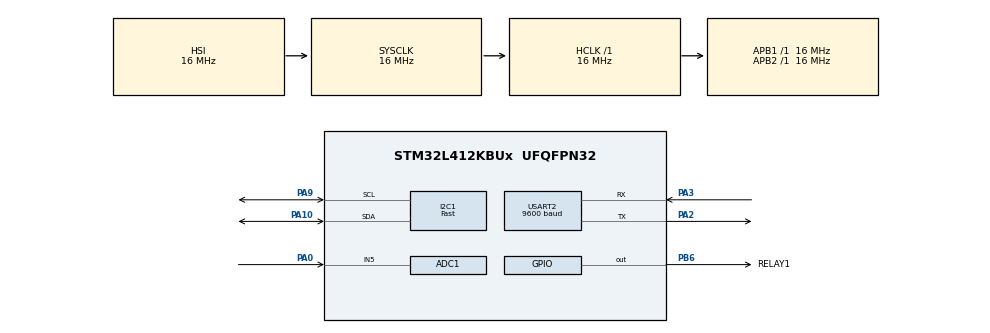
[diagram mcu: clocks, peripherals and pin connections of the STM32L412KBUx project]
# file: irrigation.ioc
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ADC1.Channel-0\#ChannelRegularConversion=ADC_CHANNEL_5
ADC1.NbrOfConversionFlag=1
ADC1.OffsetNumber-0\#ChannelRegularConversion=ADC_OFFSET_NONE
ADC1.Rank-0\#ChannelRegularConversion=1
ADC1.SamplingTime-0\#ChannelRegularConversion=ADC_SAMPLETIME_2CYCLES_5
ADC1.master=1
I2C1.I2C_Speed_Mode=I2C_Fast
I2C1.Timing=0x00300617
Mcu.Family=STM32L4
Mcu.Name=STM32L412KBUx
Mcu.Package=UFQFPN32
NVIC.PriorityGroup=NVIC_PRIORITYGROUP_4
NVIC.RTC_WKUP_IRQn=true\:0\:0\:false\:false\:true\:true\:true\:true
PA0-CK_IN.Signal=ADCx_IN5
PA10.Mode=I2C
PA10.Signal=I2C1_SDA
PA13\ (JTMS/SWDIO).Mode=Serial_Wire
PA13\ (JTMS/SWDIO).Signal=SYS_JTMS-SWDIO
PA14\ (JTCK/SWCLK).Mode=Serial_Wire
PA14\ (JTCK/SWCLK).Signal=SYS_JTCK-SWCLK
PA2.Mode=Asynchronous
PA2.Signal=USART2_TX
PA3.Mode=Asynchronous
PA3.Signal=USART2_RX
PA9.Mode=I2C
PA9.Signal=I2C1_SCL
PB6.GPIO_Label=RELAY1
PB6.PinState=GPIO_PIN_SET
PB6.Signal=GPIO_Output
ProjectManager.HeapSize=0x200
ProjectManager.StackSize=0x400
ProjectManager.TargetToolchain=CMake
RCC.ADCFreq_Value=16000000
RCC.AHBFreq_Value=16000000
RCC.APB1Freq_Value=16000000
RCC.APB1TimFreq_Value=16000000
RCC.APB2Freq_Value=16000000
RCC.APB2TimFreq_Value=16000000
RCC.CortexFreq_Value=16000000
RCC.HCLKFreq_Value=16000000
RCC.HSE_VALUE=8000000
RCC.HSI48_VALUE=48000000
RCC.HSI_VALUE=16000000
RCC.LSE_VALUE=32768
RCC.MSI_VALUE=4000000
RCC.SYSCLKFreq_VALUE=16000000
RCC.SYSCLKSource=RCC_SYSCLKSOURCE_HSI
RCC.USBFreq_Value=4000000
RCC.VCOOutputFreq_Value=32000000
RTC.WakeUpClock=RTC_WAKEUPCLOCK_CK_SPRE_16BITS
RTC.WakeUpCounter=600
SH.ADCx_IN5.0=ADC1_IN5,IN5-Single-Ended
USART2.BaudRate=9600
USART2.VirtualMode-Asynchronous=VM_ASYNC
USART2.WordLength=WORDLENGTH_7B
VP_RTC_VS_RTC_Activate.Mode=RTC_Enabled
VP_RTC_VS_RTC_WakeUp_intern.Mode=WakeUp
board=custom

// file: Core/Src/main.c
/* USER CODE BEGIN Header */
/**
  ******************************************************************************
  * @file           : main.c
  * @brief          : Main program body
  ******************************************************************************
  * @attention
  *
  * Copyright (c) 2026 STMicroelectronics.
  * All rights reserved.
  *
  * This software is licensed under terms that can be found in the LICENSE file
  * in the root directory of this software component.
  * If no LICENSE file comes with this software, it is provided AS-IS.
  *
  ******************************************************************************
  */
/* USER CODE END Header */
#include "main.h"

/* USER CODE BEGIN Includes */
#include "sh1106.h"
#include "irrigation.h"
#include "stm32l4xx_hal.h"
#include "stm32l4xx_hal_pwr.h"
/* USER CODE END Includes */

ADC_HandleTypeDef hadc1;

I2C_HandleTypeDef hi2c1;

RTC_HandleTypeDef hrtc;

UART_HandleTypeDef huart2;

void SystemClock_Config(void);
static void MX_GPIO_Init(void);
static void MX_ADC1_Init(void);
static void MX_I2C1_Init(void);
static void MX_USART2_UART_Init(void);
static void MX_RTC_Init(void);

int main(void)
{

  /* MCU Configuration--------------------------------------------------------*/

  /* Reset of all peripherals, Initializes the Flash interface and the Systick. */
  HAL_Init();

  /* Configure the system clock */
  SystemClock_Config();

  /* Initialize all configured peripherals */
  MX_GPIO_Init();
  MX_ADC1_Init();
  MX_I2C1_Init();
  MX_USART2_UART_Init();
  MX_RTC_Init();
  /* USER CODE BEGIN 2 */
  sh1106_init(&hi2c1);
  uint8_t cycle = 0;
  uint32_t moisture1, moisture2, moisture3;
  /* USER CODE END 2 */

  /* Infinite loop */
  /* USER CODE BEGIN WHILE */
  while (1)
  {
    cycle = cycle % 5;
    get_moisture(&moisture1, &moisture2, &moisture3);
    update_display_moisture(moisture1, moisture2, moisture3);
    if (cycle == 0)
    {
      irrigate();
    }
    cycle++;
    HAL_Delay(1000);
    // HAL_SuspendTick();
    // HAL_PWR_EnterSTOPMode(PWR_LOWPOWERREGULATOR_ON, PWR_STOPENTRY_WFI);

    // // wake up
    // SystemClock_Config();
    // HAL_ResumeTick();
    // irrigate();

    /* USER CODE END WHILE */

  }
}

void SystemClock_Config(void)
{
  RCC_OscInitTypeDef RCC_OscInitStruct = {0};
  RCC_ClkInitTypeDef RCC_ClkInitStruct = {0};

  /** Configure the main internal regulator output voltage
  */
  if (HAL_PWREx_ControlVoltageScaling(PWR_REGULATOR_VOLTAGE_SCALE1) != HAL_OK)
  {
    Error_Handler();
  }

  /** Initializes the RCC Oscillators according to the specified parameters
  * in the RCC_OscInitTypeDef structure.
  */
  RCC_OscInitStruct.OscillatorType = RCC_OSCILLATORTYPE_HSI|RCC_OSCILLATORTYPE_LSI;
  RCC_OscInitStruct.HSIState = RCC_HSI_ON;
  RCC_OscInitStruct.HSICalibrationValue = RCC_HSICALIBRATION_DEFAULT;
  RCC_OscInitStruct.LSIState = RCC_LSI_ON;
  RCC_OscInitStruct.PLL.PLLState = RCC_PLL_NONE;
  if (HAL_RCC_OscConfig(&RCC_OscInitStruct) != HAL_OK)
  {
    Error_Handler();
  }

  /** Initializes the CPU, AHB and APB buses clocks
  */
  RCC_ClkInitStruct.ClockType = RCC_CLOCKTYPE_HCLK|RCC_CLOCKTYPE_SYSCLK
                              |RCC_CLOCKTYPE_PCLK1|RCC_CLOCKTYPE_PCLK2;
  RCC_ClkInitStruct.SYSCLKSource = RCC_SYSCLKSOURCE_HSI;
  RCC_ClkInitStruct.AHBCLKDivider = RCC_SYSCLK_DIV1;
  RCC_ClkInitStruct.APB1CLKDivider = RCC_HCLK_DIV1;
  RCC_ClkInitStruct.APB2CLKDivider = RCC_HCLK_DIV1;

  if (HAL_RCC_ClockConfig(&RCC_ClkInitStruct, FLASH_LATENCY_0) != HAL_OK)
  {
    Error_Handler();
  }
}

static void MX_ADC1_Init(void)
{

  ADC_MultiModeTypeDef multimode = {0};
  ADC_ChannelConfTypeDef sConfig = {0};

  /** Common config
  */
  hadc1.Instance = ADC1;
  hadc1.Init.ClockPrescaler = ADC_CLOCK_ASYNC_DIV1;
  hadc1.Init.Resolution = ADC_RESOLUTION_12B;
  hadc1.Init.DataAlign = ADC_DATAALIGN_RIGHT;
  hadc1.Init.ScanConvMode = ADC_SCAN_DISABLE;
  hadc1.Init.EOCSelection = ADC_EOC_SINGLE_CONV;
  hadc1.Init.LowPowerAutoWait = DISABLE;
  hadc1.Init.ContinuousConvMode = DISABLE;
  hadc1.Init.NbrOfConversion = 1;
  hadc1.Init.DiscontinuousConvMode = DISABLE;
  hadc1.Init.ExternalTrigConv = ADC_SOFTWARE_START;
  hadc1.Init.ExternalTrigConvEdge = ADC_EXTERNALTRIGCONVEDGE_NONE;
  hadc1.Init.DMAContinuousRequests = DISABLE;
  hadc1.Init.Overrun = ADC_OVR_DATA_PRESERVED;
  hadc1.Init.OversamplingMode = DISABLE;
  if (HAL_ADC_Init(&hadc1) != HAL_OK)
  {
    Error_Handler();
  }

  /** Configure the ADC multi-mode
  */
  multimode.Mode = ADC_MODE_INDEPENDENT;
  if (HAL_ADCEx_MultiModeConfigChannel(&hadc1, &multimode) != HAL_OK)
  {
    Error_Handler();
  }

  /** Configure Regular Channel
  */
  sConfig.Channel = ADC_CHANNEL_5;
  sConfig.Rank = ADC_REGULAR_RANK_1;
  sConfig.SamplingTime = ADC_SAMPLETIME_2CYCLES_5;
  sConfig.SingleDiff = ADC_SINGLE_ENDED;
  sConfig.OffsetNumber = ADC_OFFSET_NONE;
  sConfig.Offset = 0;
  if (HAL_ADC_ConfigChannel(&hadc1, &sConfig) != HAL_OK)
  {
    Error_Handler();
  }

}

static void MX_I2C1_Init(void)
{

  hi2c1.Instance = I2C1;
  hi2c1.Init.Timing = 0x00300617;
  hi2c1.Init.OwnAddress1 = 0;
  hi2c1.Init.AddressingMode = I2C_ADDRESSINGMODE_7BIT;
  hi2c1.Init.DualAddressMode = I2C_DUALADDRESS_DISABLE;
  hi2c1.Init.OwnAddress2 = 0;
  hi2c1.Init.OwnAddress2Masks = I2C_OA2_NOMASK;
  hi2c1.Init.GeneralCallMode = I2C_GENERALCALL_DISABLE;
  hi2c1.Init.NoStretchMode = I2C_NOSTRETCH_DISABLE;
  if (HAL_I2C_Init(&hi2c1) != HAL_OK)
  {
    Error_Handler();
  }

  /** Configure Analogue filter
  */
  if (HAL_I2CEx_ConfigAnalogFilter(&hi2c1, I2C_ANALOGFILTER_ENABLE) != HAL_OK)
  {
    Error_Handler();
  }

  /** Configure Digital filter
  */
  if (HAL_I2CEx_ConfigDigitalFilter(&hi2c1, 0) != HAL_OK)
  {
    Error_Handler();
  }

}

static void MX_RTC_Init(void)
{

  /** Initialize RTC Only
  */
  hrtc.Instance = RTC;
  hrtc.Init.HourFormat = RTC_HOURFORMAT_24;
  hrtc.Init.AsynchPrediv = 127;
  hrtc.Init.SynchPrediv = 255;
  hrtc.Init.OutPut = RTC_OUTPUT_DISABLE;
  hrtc.Init.OutPutRemap = RTC_OUTPUT_REMAP_NONE;
  hrtc.Init.OutPutPolarity = RTC_OUTPUT_POLARITY_HIGH;
  hrtc.Init.OutPutType = RTC_OUTPUT_TYPE_OPENDRAIN;
  hrtc.Init.OutPutPullUp = RTC_OUTPUT_PULLUP_NONE;
  if (HAL_RTC_Init(&hrtc) != HAL_OK)
  {
    Error_Handler();
  }

  /** Enable the WakeUp
  */
  if (HAL_RTCEx_SetWakeUpTimer_IT(&hrtc, 600, RTC_WAKEUPCLOCK_CK_SPRE_16BITS, 0) != HAL_OK)
  {
    Error_Handler();
  }

}

static void MX_USART2_UART_Init(void)
{

  huart2.Instance = USART2;
  huart2.Init.BaudRate = 9600;
  huart2.Init.WordLength = UART_WORDLENGTH_7B;
  huart2.Init.StopBits = UART_STOPBITS_1;
  huart2.Init.Parity = UART_PARITY_NONE;
  huart2.Init.Mode = UART_MODE_TX_RX;
  huart2.Init.HwFlowCtl = UART_HWCONTROL_NONE;
  huart2.Init.OverSampling = UART_OVERSAMPLING_16;
  huart2.Init.OneBitSampling = UART_ONE_BIT_SAMPLE_DISABLE;
  huart2.AdvancedInit.AdvFeatureInit = UART_ADVFEATURE_NO_INIT;
  if (HAL_UART_Init(&huart2) != HAL_OK)
  {
    Error_Handler();
  }

}

static void MX_GPIO_Init(void)
{
  GPIO_InitTypeDef GPIO_InitStruct = {0};

  /* GPIO Ports Clock Enable */
  __HAL_RCC_GPIOA_CLK_ENABLE();
  __HAL_RCC_GPIOB_CLK_ENABLE();

  /*Configure GPIO pin Output Level */
  HAL_GPIO_WritePin(RELAY1_GPIO_Port, RELAY1_Pin, GPIO_PIN_SET);

  /*Configure GPIO pin : RELAY1_Pin */
  GPIO_InitStruct.Pin = RELAY1_Pin;
  GPIO_InitStruct.Mode = GPIO_MODE_OUTPUT_PP;
  GPIO_InitStruct.Pull = GPIO_NOPULL;
  GPIO_InitStruct.Speed = GPIO_SPEED_FREQ_LOW;
  HAL_GPIO_Init(RELAY1_GPIO_Port, &GPIO_InitStruct);

}

void Error_Handler(void)
{
  __disable_irq();
  while (1)
  {
  }
}
